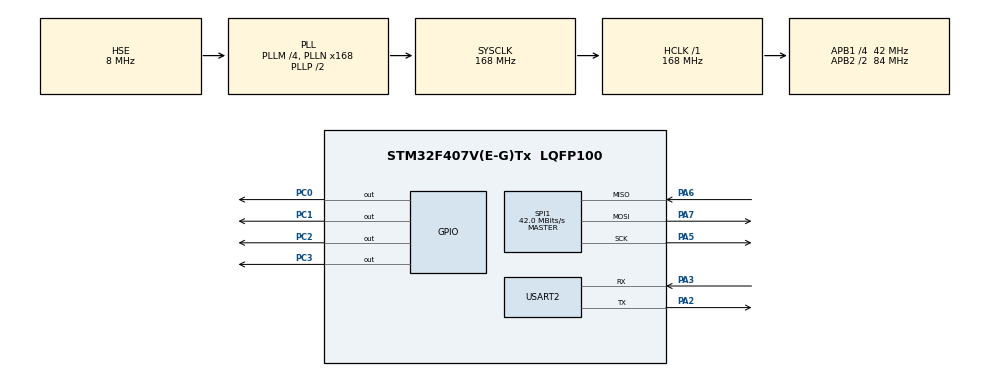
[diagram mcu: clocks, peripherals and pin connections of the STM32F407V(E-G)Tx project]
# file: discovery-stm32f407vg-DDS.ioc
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Mcu.Family=STM32F4
RCC.PLLSourceVirtual=RCC_PLLSOURCE_HSE
PA6.Mode=Full_Duplex_Master
PH0-OSC_IN.Signal=RCC_OSC_IN
RCC.CortexFreq_Value=168000000
PA7.Mode=Full_Duplex_Master
SPI1.VirtualType=VM_MASTER
PC2.Signal=GPIO_Output
PC0.Signal=GPIO_Output
RCC.APB1CLKDivider=RCC_HCLK_DIV4
RCC.SYSCLKSource=RCC_SYSCLKSOURCE_PLLCLK
ProjectManager.StackSize=0x400
PA13.Signal=SYS_JTMS-SWDIO
PA3.Mode=Asynchronous
ProjectManager.TargetToolchain=STM32CubeIDE
SPI1.Direction=SPI_DIRECTION_2LINES
RCC.HCLKFreq_Value=168000000
RCC.APB2TimFreq_Value=168000000
SPI1.CalculateBaudRate=42.0 MBits/s
PC3.Signal=GPIO_Output
RCC.LSE_VALUE=32768
RCC.AHBFreq_Value=168000000
PH0-OSC_IN.Mode=HSE-External-Oscillator
PA5.Signal=SPI1_SCK
RCC.HSE_VALUE=8000000
board=custom
RCC.VCOOutputFreq_Value=336000000
RCC.APB2Freq_Value=84000000
SPI1.Mode=SPI_MODE_MASTER
PA14.Mode=Serial_Wire
PH1-OSC_OUT.Signal=RCC_OSC_OUT
PA13.Mode=Serial_Wire
Mcu.Name=STM32F407V(E-G)Tx
PA2.Signal=USART2_TX
PH1-OSC_OUT.Mode=HSE-External-Oscillator
RCC.48MHZClocksFreq_Value=84000000
RCC.SYSCLKFreq_VALUE=168000000
Mcu.Package=LQFP100
PA6.Signal=SPI1_MISO
USART2.VirtualMode=VM_ASYNC
PA14.Signal=SYS_JTCK-SWCLK
ProjectManager.HeapSize=0x200
RCC.HSI_VALUE=16000000
NVIC.PriorityGroup=NVIC_PRIORITYGROUP_4
RCC.APB2CLKDivider=RCC_HCLK_DIV2
RCC.PLLM=4
RCC.PLLN=168
RCC.APB1TimFreq_Value=84000000
PA2.Mode=Asynchronous
RCC.APB1Freq_Value=42000000
PC1.Signal=GPIO_Output
PA3.Signal=USART2_RX
PA5.Mode=Full_Duplex_Master
PA7.Signal=SPI1_MOSI

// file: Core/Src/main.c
/* USER CODE BEGIN Header */
/**
  ******************************************************************************
  * @file           : main.c
  * @brief          : Main program body
  ******************************************************************************
  * @attention
  *
  * <h2><center>&copy; Copyright (c) 2021 STMicroelectronics.
  * All rights reserved.</center></h2>
  *
  * This software component is licensed by ST under BSD 3-Clause license,
  * the "License"; You may not use this file except in compliance with the
  * License. You may obtain a copy of the License at:
  *                        opensource.org/licenses/BSD-3-Clause
  *
  ******************************************************************************
  */
/* USER CODE END Header */
#include "main.h"

/* USER CODE BEGIN Includes */
#include "AD9833.h"
#include "AD5227.h"
/* USER CODE END Includes */

SPI_HandleTypeDef hspi1;

UART_HandleTypeDef huart2;

void SystemClock_Config(void);
static void MX_GPIO_Init(void);
static void MX_SPI1_Init(void);
static void MX_USART2_UART_Init(void);

int main(void)
{

  /* MCU Configuration--------------------------------------------------------*/

  /* Reset of all peripherals, Initializes the Flash interface and the Systick. */
  HAL_Init();

  /* Configure the system clock */
  SystemClock_Config();

  /* Initialize all configured peripherals */
  MX_GPIO_Init();
  MX_SPI1_Init();
  MX_USART2_UART_Init();
  /* USER CODE BEGIN 2 */
  AD9833_Init(0,5000,0);   // Initializing AD9833

  //AD5227_StepUp();

//  AD5227_StepDown();
//
//  AD5227_StepDown();

  for(int i = 0; i<60; i++) {
	  HAL_Delay(50);
	  AD5227_StepUp();
  }

//  for(int i = 0; i<60; i++) {
//	  HAL_Delay(50);
//	  AD5227_StepDown();
//  }

  /* USER CODE END 2 */

  /* Infinite loop */
  /* USER CODE BEGIN WHILE */
  while (1)
  {
//	  for(int i = 0; i<60; i++) {
//		  HAL_Delay(50);
//		  AD5227_StepUp();
//	  }
//
//	  for(int i = 0; i<60; i++) {
//		  HAL_Delay(50);
//		  AD5227_StepDown();
//	  }

    /* USER CODE END WHILE */

  }
}

void SystemClock_Config(void)
{
  RCC_OscInitTypeDef RCC_OscInitStruct = {0};
  RCC_ClkInitTypeDef RCC_ClkInitStruct = {0};

  /** Configure the main internal regulator output voltage
  */
  __HAL_RCC_PWR_CLK_ENABLE();
  __HAL_PWR_VOLTAGESCALING_CONFIG(PWR_REGULATOR_VOLTAGE_SCALE1);
  /** Initializes the RCC Oscillators according to the specified parameters
  * in the RCC_OscInitTypeDef structure.
  */
  RCC_OscInitStruct.OscillatorType = RCC_OSCILLATORTYPE_HSE;
  RCC_OscInitStruct.HSEState = RCC_HSE_ON;
  RCC_OscInitStruct.PLL.PLLState = RCC_PLL_ON;
  RCC_OscInitStruct.PLL.PLLSource = RCC_PLLSOURCE_HSE;
  RCC_OscInitStruct.PLL.PLLM = 4;
  RCC_OscInitStruct.PLL.PLLN = 168;
  RCC_OscInitStruct.PLL.PLLP = RCC_PLLP_DIV2;
  RCC_OscInitStruct.PLL.PLLQ = 4;
  if (HAL_RCC_OscConfig(&RCC_OscInitStruct) != HAL_OK)
  {
    Error_Handler();
  }
  /** Initializes the CPU, AHB and APB buses clocks
  */
  RCC_ClkInitStruct.ClockType = RCC_CLOCKTYPE_HCLK|RCC_CLOCKTYPE_SYSCLK
                              |RCC_CLOCKTYPE_PCLK1|RCC_CLOCKTYPE_PCLK2;
  RCC_ClkInitStruct.SYSCLKSource = RCC_SYSCLKSOURCE_PLLCLK;
  RCC_ClkInitStruct.AHBCLKDivider = RCC_SYSCLK_DIV1;
  RCC_ClkInitStruct.APB1CLKDivider = RCC_HCLK_DIV4;
  RCC_ClkInitStruct.APB2CLKDivider = RCC_HCLK_DIV2;

  if (HAL_RCC_ClockConfig(&RCC_ClkInitStruct, FLASH_LATENCY_5) != HAL_OK)
  {
    Error_Handler();
  }
}

static void MX_SPI1_Init(void)
{

  /* SPI1 parameter configuration*/
  hspi1.Instance = SPI1;
  hspi1.Init.Mode = SPI_MODE_MASTER;
  hspi1.Init.Direction = SPI_DIRECTION_2LINES;
  hspi1.Init.DataSize = SPI_DATASIZE_8BIT;
  hspi1.Init.CLKPolarity = SPI_POLARITY_LOW;
  hspi1.Init.CLKPhase = SPI_PHASE_1EDGE;
  hspi1.Init.NSS = SPI_NSS_SOFT;
  hspi1.Init.BaudRatePrescaler = SPI_BAUDRATEPRESCALER_2;
  hspi1.Init.FirstBit = SPI_FIRSTBIT_MSB;
  hspi1.Init.TIMode = SPI_TIMODE_DISABLE;
  hspi1.Init.CRCCalculation = SPI_CRCCALCULATION_DISABLE;
  hspi1.Init.CRCPolynomial = 10;
  if (HAL_SPI_Init(&hspi1) != HAL_OK)
  {
    Error_Handler();
  }

}

static void MX_USART2_UART_Init(void)
{

  huart2.Instance = USART2;
  huart2.Init.BaudRate = 115200;
  huart2.Init.WordLength = UART_WORDLENGTH_8B;
  huart2.Init.StopBits = UART_STOPBITS_1;
  huart2.Init.Parity = UART_PARITY_NONE;
  huart2.Init.Mode = UART_MODE_TX_RX;
  huart2.Init.HwFlowCtl = UART_HWCONTROL_NONE;
  huart2.Init.OverSampling = UART_OVERSAMPLING_16;
  if (HAL_UART_Init(&huart2) != HAL_OK)
  {
    Error_Handler();
  }

}

static void MX_GPIO_Init(void)
{
  GPIO_InitTypeDef GPIO_InitStruct = {0};

  /* GPIO Ports Clock Enable */
  __HAL_RCC_GPIOH_CLK_ENABLE();
  __HAL_RCC_GPIOC_CLK_ENABLE();
  __HAL_RCC_GPIOA_CLK_ENABLE();

  /*Configure GPIO pin Output Level */
  HAL_GPIO_WritePin(GPIOC, GPIO_PIN_0|GPIO_PIN_1|GPIO_PIN_2|GPIO_PIN_3, GPIO_PIN_RESET);

  /*Configure GPIO pins : PC0 PC1 PC2 PC3 */
  GPIO_InitStruct.Pin = GPIO_PIN_0|GPIO_PIN_1|GPIO_PIN_2|GPIO_PIN_3;
  GPIO_InitStruct.Mode = GPIO_MODE_OUTPUT_PP;
  GPIO_InitStruct.Pull = GPIO_NOPULL;
  GPIO_InitStruct.Speed = GPIO_SPEED_FREQ_LOW;
  HAL_GPIO_Init(GPIOC, &GPIO_InitStruct);

}

void Error_Handler(void)
{
  __disable_irq();
  while (1)
  {
  }
}

/************************ (C) COPYRIGHT STMicroelectronics *****END OF FILE****/
